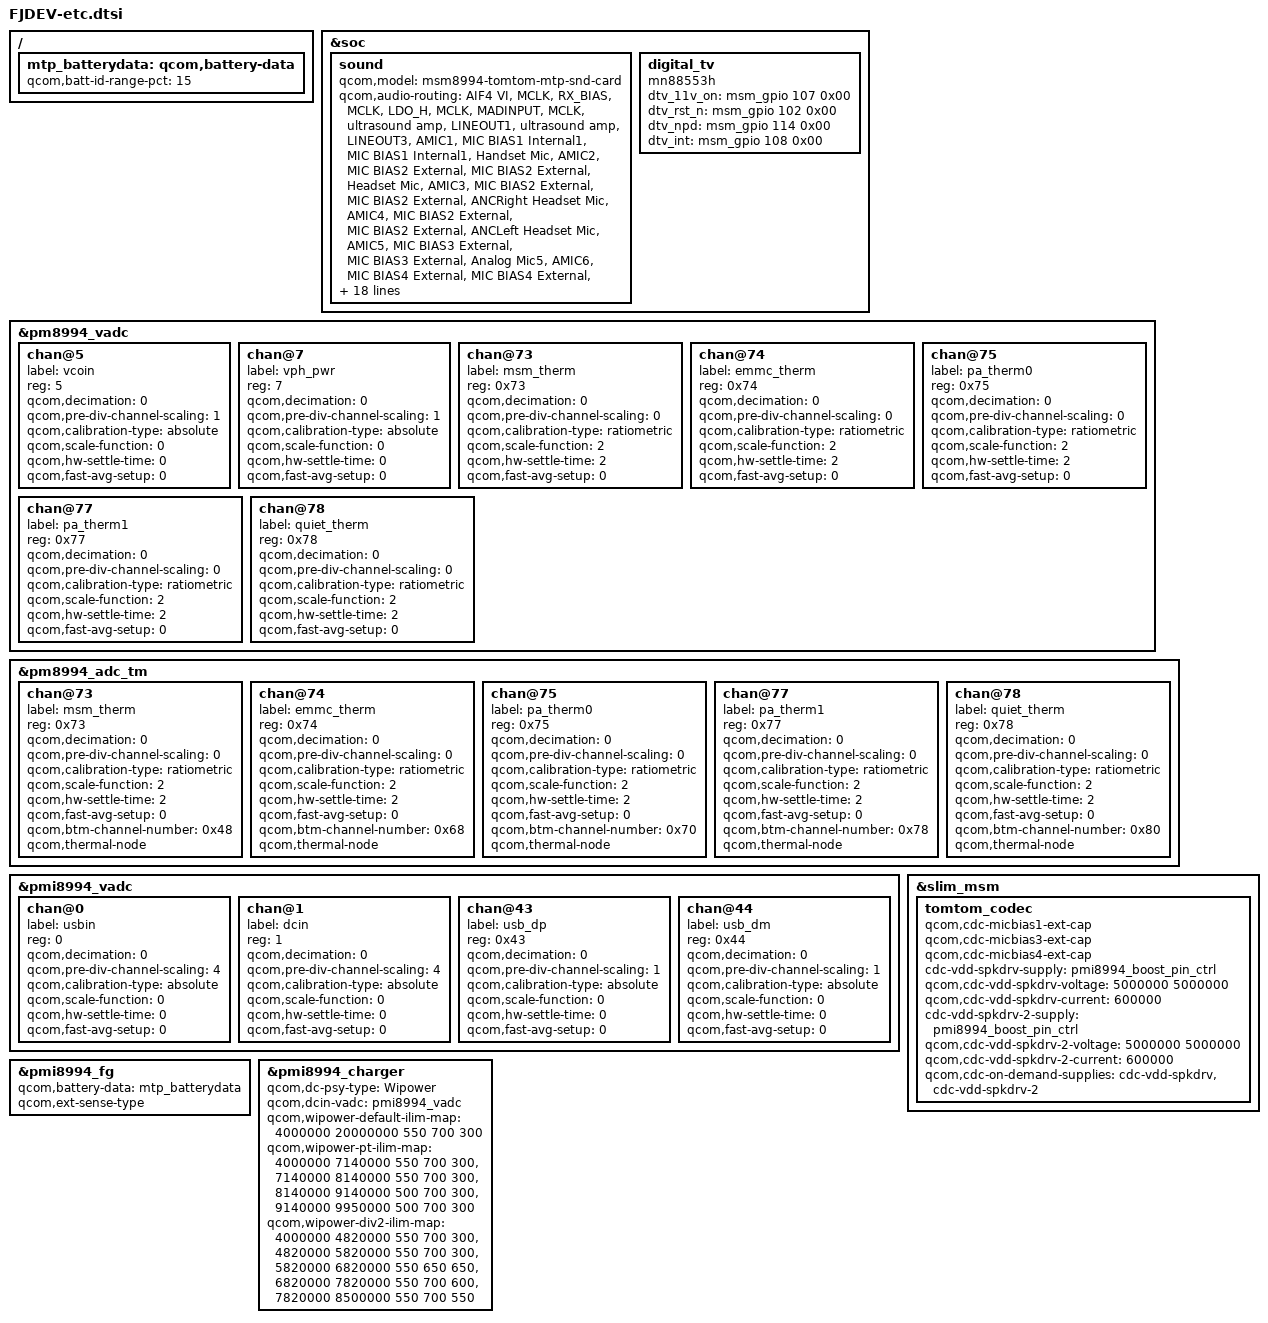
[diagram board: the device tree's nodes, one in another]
/*
 * FJDEV-etc.dtsi
 *
 * Copyright(C) 2015 FUJITSU LIMITED
 *
 * This program is free software; you can redistribute it and/or
 * modify it under the terms of the GNU General Public License
 * as published by the Free Software Foundation; version 2
 * of the License.
 *
 * This program is distributed in the hope that it will be useful,
 * but WITHOUT ANY WARRANTY; without even the implied warranty of
 * MERCHANTABILITY or FITNESS FOR A PARTICULAR PURPOSE. See the
 * GNU General Public License for more details.
 *
 * You should have received a copy of the GNU General Public License
 * along with this program; if not, write to the Free Software
 * Foundation, Inc., 59 Temple Place - Suite 330, Boston, MA 02111-1307, USA.
 */

&soc {
	sound {
		qcom,model = "msm8994-tomtom-mtp-snd-card";

		qcom,audio-routing =
			"AIF4 VI", "MCLK",
			"RX_BIAS", "MCLK",
			"LDO_H", "MCLK",
			"MADINPUT", "MCLK",
			"ultrasound amp", "LINEOUT1",
			"ultrasound amp", "LINEOUT3",
			"AMIC1", "MIC BIAS1 Internal1",
			"MIC BIAS1 Internal1", "Handset Mic",
			"AMIC2", "MIC BIAS2 External",
			"MIC BIAS2 External", "Headset Mic",
			"AMIC3", "MIC BIAS2 External",
			"MIC BIAS2 External", "ANCRight Headset Mic",
			"AMIC4", "MIC BIAS2 External",
			"MIC BIAS2 External", "ANCLeft Headset Mic",
			"AMIC5", "MIC BIAS3 External",
			"MIC BIAS3 External", "Analog Mic5",
			"AMIC6", "MIC BIAS4 External",
			"MIC BIAS4 External", "Analog Mic6",
			"DMIC1", "MIC BIAS1 External",
			"MIC BIAS1 External", "Digital Mic1",
			"DMIC2", "MIC BIAS1 External",
			"MIC BIAS1 External", "Digital Mic2",
			"DMIC3", "MIC BIAS3 External",
			"MIC BIAS3 External", "Digital Mic3",
			"DMIC4", "MIC BIAS3 External",
			"MIC BIAS3 External", "Digital Mic4",
			"DMIC5", "MIC BIAS4 External",
			"MIC BIAS4 External", "Digital Mic5",
			"DMIC6", "MIC BIAS4 External",
			"MIC BIAS4 External", "Digital Mic6";

		qcom,us-euro-gpios = <&pm8994_mpps 2 0>;
		qcom,cdc-micbias2-headset-only;
		qcom,mbhc-audio-jack-type = "6-pole-jack";
		qcom,ext-ult-spk-amp-gpio = <&pmi8994_gpios 1 0>;
		qcom,hdmi-audio-rx;
		asoc-codec = <&stub_codec>, <&hdmi_audio>;
		asoc-codec-names = "msm-stub-codec.1", "msm-hdmi-audio-codec-rx";
	};
};

&pm8994_vadc {
	chan@5 {
		label = "vcoin";
		reg = <5>;
		qcom,decimation = <0>;
		qcom,pre-div-channel-scaling = <1>;
		qcom,calibration-type = "absolute";
		qcom,scale-function = <0>;
		qcom,hw-settle-time = <0>;
		qcom,fast-avg-setup = <0>;
	};

	chan@7 {
		label = "vph_pwr";
		reg = <7>;
		qcom,decimation = <0>;
		qcom,pre-div-channel-scaling = <1>;
		qcom,calibration-type = "absolute";
		qcom,scale-function = <0>;
		qcom,hw-settle-time = <0>;
		qcom,fast-avg-setup = <0>;
	};

	chan@73 {
		label = "msm_therm";
		reg = <0x73>;
		qcom,decimation = <0>;
		qcom,pre-div-channel-scaling = <0>;
		qcom,calibration-type = "ratiometric";
		qcom,scale-function = <2>;
		qcom,hw-settle-time = <2>;
		qcom,fast-avg-setup = <0>;
	};

	chan@74 {
		label = "emmc_therm";
		reg = <0x74>;
		qcom,decimation = <0>;
		qcom,pre-div-channel-scaling = <0>;
		qcom,calibration-type = "ratiometric";
		qcom,scale-function = <2>;
		qcom,hw-settle-time = <2>;
		qcom,fast-avg-setup = <0>;
	};

	chan@75 {
		label = "pa_therm0";
		reg = <0x75>;
		qcom,decimation = <0>;
		qcom,pre-div-channel-scaling = <0>;
		qcom,calibration-type = "ratiometric";
		qcom,scale-function = <2>;
		qcom,hw-settle-time = <2>;
		qcom,fast-avg-setup = <0>;
	};

	chan@77 {
		label = "pa_therm1";
		reg = <0x77>;
		qcom,decimation = <0>;
		qcom,pre-div-channel-scaling = <0>;
		qcom,calibration-type = "ratiometric";
		qcom,scale-function = <2>;
		qcom,hw-settle-time = <2>;
		qcom,fast-avg-setup = <0>;
	};

	chan@78 {
		label = "quiet_therm";
		reg = <0x78>;
		qcom,decimation = <0>;
		qcom,pre-div-channel-scaling = <0>;
		qcom,calibration-type = "ratiometric";
		qcom,scale-function = <2>;
		qcom,hw-settle-time = <2>;
		qcom,fast-avg-setup = <0>;
	};
};

&pm8994_adc_tm {
	chan@73 {
		label = "msm_therm";
		reg = <0x73>;
		qcom,decimation = <0>;
		qcom,pre-div-channel-scaling = <0>;
		qcom,calibration-type = "ratiometric";
		qcom,scale-function = <2>;
		qcom,hw-settle-time = <2>;
		qcom,fast-avg-setup = <0>;
		qcom,btm-channel-number = <0x48>;
		qcom,thermal-node;
	};

	chan@74 {
		label = "emmc_therm";
		reg = <0x74>;
		qcom,decimation = <0>;
		qcom,pre-div-channel-scaling = <0>;
		qcom,calibration-type = "ratiometric";
		qcom,scale-function = <2>;
		qcom,hw-settle-time = <2>;
		qcom,fast-avg-setup = <0>;
		qcom,btm-channel-number = <0x68>;
		qcom,thermal-node;
	};

	chan@75 {
		label = "pa_therm0";
		reg = <0x75>;
		qcom,decimation = <0>;
		qcom,pre-div-channel-scaling = <0>;
		qcom,calibration-type = "ratiometric";
		qcom,scale-function = <2>;
		qcom,hw-settle-time = <2>;
		qcom,fast-avg-setup = <0>;
		qcom,btm-channel-number = <0x70>;
		qcom,thermal-node;
	};

	chan@77 {
		label = "pa_therm1";
		reg = <0x77>;
		qcom,decimation = <0>;
		qcom,pre-div-channel-scaling = <0>;
		qcom,calibration-type = "ratiometric";
		qcom,scale-function = <2>;
		qcom,hw-settle-time = <2>;
		qcom,fast-avg-setup = <0>;
		qcom,btm-channel-number = <0x78>;
		qcom,thermal-node;
	};

	chan@78 {
		label = "quiet_therm";
		reg = <0x78>;
		qcom,decimation = <0>;
		qcom,pre-div-channel-scaling = <0>;
		qcom,calibration-type = "ratiometric";
		qcom,scale-function = <2>;
		qcom,hw-settle-time = <2>;
		qcom,fast-avg-setup = <0>;
		qcom,btm-channel-number = <0x80>;
		qcom,thermal-node;
	};
};

&pmi8994_vadc {
	chan@0 {
		label = "usbin";
		reg = <0>;
		qcom,decimation = <0>;
		qcom,pre-div-channel-scaling = <4>;
		qcom,calibration-type = "absolute";
		qcom,scale-function = <0>;
		qcom,hw-settle-time = <0>;
		qcom,fast-avg-setup = <0>;
	};

	chan@1 {
		label = "dcin";
		reg = <1>;
		qcom,decimation = <0>;
		qcom,pre-div-channel-scaling = <4>;
		qcom,calibration-type = "absolute";
		qcom,scale-function = <0>;
		qcom,hw-settle-time = <0>;
		qcom,fast-avg-setup = <0>;
	};

	chan@43 {
		label = "usb_dp";
		reg = <0x43>;
		qcom,decimation = <0>;
		qcom,pre-div-channel-scaling = <1>;
		qcom,calibration-type = "absolute";
		qcom,scale-function = <0>;
		qcom,hw-settle-time = <0>;
		qcom,fast-avg-setup = <0>;
	};

	chan@44 {
		label = "usb_dm";
		reg = <0x44>;
		qcom,decimation = <0>;
		qcom,pre-div-channel-scaling = <1>;
		qcom,calibration-type = "absolute";
		qcom,scale-function = <0>;
		qcom,hw-settle-time = <0>;
		qcom,fast-avg-setup = <0>;
	};
};

&slim_msm {
	tomtom_codec {
		qcom,cdc-micbias1-ext-cap;
		qcom,cdc-micbias3-ext-cap;
		qcom,cdc-micbias4-ext-cap;
		cdc-vdd-spkdrv-supply = <&pmi8994_boost_pin_ctrl>;
		qcom,cdc-vdd-spkdrv-voltage = <5000000 5000000>;
		qcom,cdc-vdd-spkdrv-current = <600000>;

		cdc-vdd-spkdrv-2-supply = <&pmi8994_boost_pin_ctrl>;
		qcom,cdc-vdd-spkdrv-2-voltage = <5000000 5000000>;
		qcom,cdc-vdd-spkdrv-2-current = <600000>;

		qcom,cdc-on-demand-supplies = "cdc-vdd-spkdrv",
					      "cdc-vdd-spkdrv-2";
	};
};

/{
	mtp_batterydata: qcom,battery-data {
		qcom,batt-id-range-pct = <15>;
		#include "../../../batterydata-itech-3000mah.dtsi"
	};
};

&pmi8994_fg {
	qcom,battery-data = <&mtp_batterydata>;
	qcom,ext-sense-type;
};

&pmi8994_charger {
	qcom,dc-psy-type = "Wipower";
	qcom,dcin-vadc = <&pmi8994_vadc>;
	qcom,wipower-default-ilim-map = <4000000 20000000 550 700 300>;
	qcom,wipower-pt-ilim-map = <4000000 7140000 550 700 300>,
					<7140000 8140000 550 700 300>,
					<8140000 9140000 500 700 300>,
					<9140000 9950000 500 700 300>;
	qcom,wipower-div2-ilim-map = <4000000 4820000 550 700 300>,
					<4820000 5820000 550 700 300>,
					<5820000 6820000 550 650 650>,
					<6820000 7820000 550 700 600>,
					<7820000 8500000 550 700 550>;
};

//FUJITSU:2016-01-04 add-s DTV
&soc {
	digital_tv {
		compatible = "mn88553h";

		dtv_11v_on = <&msm_gpio 107 0x00>;
		dtv_rst_n  = <&msm_gpio 102 0x00>;
		dtv_npd    = <&msm_gpio 114 0x00>;

		dtv_int    = <&msm_gpio 108 0x00>;
	};
};
//FUJITSU:2016-01-04 add-e DTV
